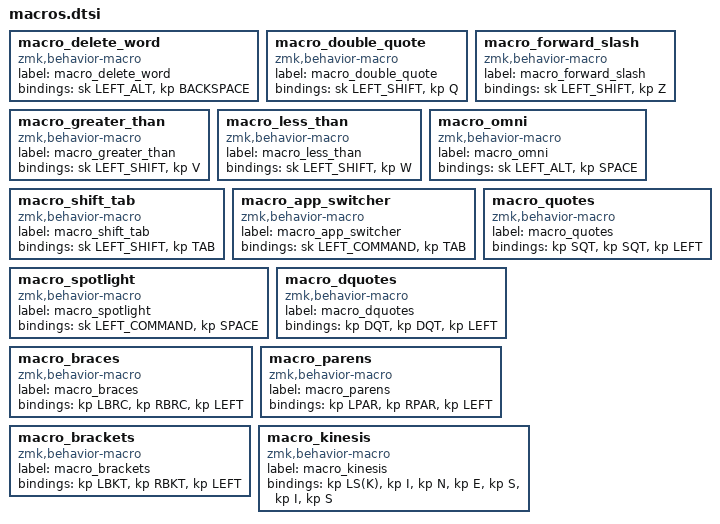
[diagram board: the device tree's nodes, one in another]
macro_delete_word: macro_delete_word{
compatible = "zmk,behavior-macro";
label = "macro_delete_word";
#binding-cells = <0>;
bindings = <&sk LEFT_ALT>, <&kp BACKSPACE>;
};
macro_double_quote: macro_double_quote{
compatible = "zmk,behavior-macro";
label = "macro_double_quote";
#binding-cells = <0>;
bindings = <&sk LEFT_SHIFT>, <&kp Q>;
};
macro_forward_slash: macro_forward_slash{
compatible = "zmk,behavior-macro";
label = "macro_forward_slash";
#binding-cells = <0>;
bindings = <&sk LEFT_SHIFT>, <&kp Z>;
};
macro_greater_than: macro_greater_than{
compatible = "zmk,behavior-macro";
label = "macro_greater_than";
#binding-cells = <0>;
bindings = <&sk LEFT_SHIFT>, <&kp V>;
};
macro_less_than: macro_less_than{
compatible = "zmk,behavior-macro";
label = "macro_less_than";
#binding-cells = <0>;
bindings = <&sk LEFT_SHIFT>, <&kp W>;
};
macro_omni: macro_omni{
compatible = "zmk,behavior-macro";
label = "macro_omni";
#binding-cells = <0>;
bindings = <&sk LEFT_ALT>, <&kp SPACE>;
};
macro_shift_tab: macro_shift_tab{
compatible = "zmk,behavior-macro";
label = "macro_shift_tab";
#binding-cells = <0>;
bindings = <&sk LEFT_SHIFT>, <&kp TAB>;
};
macro_app_switcher: macro_app_switcher{
compatible = "zmk,behavior-macro";
label = "macro_app_switcher";
#binding-cells = <0>;
bindings = <&sk LEFT_COMMAND>, <&kp TAB>;
};
macro_spotlight: macro_spotlight{
compatible = "zmk,behavior-macro";
label = "macro_spotlight";
#binding-cells = <0>;
bindings = <&sk LEFT_COMMAND>, <&kp SPACE>;
};
macro_quotes: macro_quotes{
compatible = "zmk,behavior-macro";
label = "macro_quotes";
#binding-cells = <0>;
bindings = <&kp SQT>, <&kp SQT>, <&kp LEFT>;
};
macro_dquotes: macro_dquotes{
compatible = "zmk,behavior-macro";
label = "macro_dquotes";
#binding-cells = <0>;
bindings = <&kp DQT>, <&kp DQT>, <&kp LEFT>;
};
macro_braces: macro_braces{
compatible = "zmk,behavior-macro";
label = "macro_braces";
#binding-cells = <0>;
bindings = <&kp LBRC>, <&kp RBRC>, <&kp LEFT>;
};
macro_parens: macro_parens{
compatible = "zmk,behavior-macro";
label = "macro_parens";
#binding-cells = <0>;
bindings = <&kp LPAR>, <&kp RPAR>, <&kp LEFT>;
};
macro_brackets: macro_brackets{
compatible = "zmk,behavior-macro";
label = "macro_brackets";
#binding-cells = <0>;
bindings = <&kp LBKT>, <&kp RBKT>, <&kp LEFT>;
};
macro_kinesis: macro_kinesis{
compatible = "zmk,behavior-macro";
label = "macro_kinesis";
#binding-cells = <0>;
bindings = <&kp LS(K)>, <&kp I>, <&kp N>, <&kp E>, <&kp S>, <&kp I>, <&kp S>;
};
